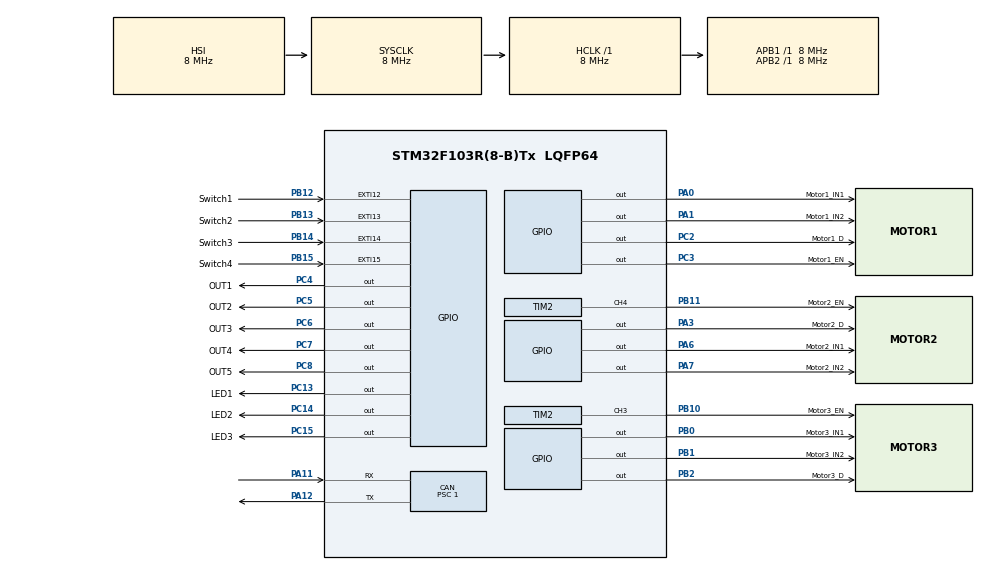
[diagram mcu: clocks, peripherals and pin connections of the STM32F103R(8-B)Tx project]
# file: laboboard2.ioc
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CAN.BS1=CAN_BS1_13TQ
CAN.BS2=CAN_BS2_2TQ
CAN.CalculateBaudRate=500000
CAN.CalculateTimeBit=2000
CAN.CalculateTimeQuantum=125.0
CAN.NART=ENABLE
CAN.Prescaler=1
Mcu.Family=STM32F1
Mcu.Name=STM32F103R(8-B)Tx
Mcu.Package=LQFP64
NVIC.CAN1_RX1_IRQn=true\:5\:0\:true\:false\:true\:true\:true\:true
NVIC.EXTI15_10_IRQn=true\:0\:0\:false\:false\:true\:true\:true\:true
NVIC.PriorityGroup=NVIC_PRIORITYGROUP_4
NVIC.TIM2_IRQn=true\:0\:0\:false\:false\:true\:true\:true\:true
NVIC.TIM3_IRQn=true\:2\:0\:true\:false\:true\:true\:true\:true
NVIC.USB_HP_CAN1_TX_IRQn=true\:5\:0\:true\:false\:true\:true\:true\:true
NVIC.USB_LP_CAN1_RX0_IRQn=true\:5\:0\:true\:false\:true\:true\:true\:true
PA0-WKUP.GPIO_Label=Motor1_IN1
PA0-WKUP.Signal=GPIO_Output
PA1.GPIO_Label=Motor1_IN2
PA1.Signal=GPIO_Output
PA11.Mode=CAN_Activate
PA11.Signal=CAN_RX
PA12.Mode=CAN_Activate
PA12.Signal=CAN_TX
PA13.Mode=Serial_Wire
PA13.Signal=SYS_JTMS-SWDIO
PA14.Mode=Serial_Wire
PA14.Signal=SYS_JTCK-SWCLK
PA3.GPIO_Label=Motor2_D
PA3.Signal=GPIO_Output
PA6.GPIO_Label=Motor2_IN1
PA6.Signal=GPIO_Output
PA7.GPIO_Label=Motor2_IN2
PA7.Signal=GPIO_Output
PB0.GPIO_Label=Motor3_IN1
PB0.Signal=GPIO_Output
PB1.GPIO_Label=Motor3_IN2
PB1.Signal=GPIO_Output
PB10.GPIO_Label=Motor3_EN
PB10.Signal=S_TIM2_CH3
PB11.GPIO_Label=Motor2_EN
PB11.Signal=S_TIM2_CH4
PB12.GPIO_Label=Switch1
PB12.GPIO_ModeDefaultEXTI=GPIO_MODE_IT_RISING_FALLING
PB12.GPIO_PuPd=GPIO_PULLDOWN
PB12.Signal=GPXTI12
PB13.GPIO_Label=Switch2
PB13.GPIO_ModeDefaultEXTI=GPIO_MODE_IT_RISING_FALLING
PB13.GPIO_PuPd=GPIO_PULLUP
PB13.Signal=GPXTI13
PB14.GPIO_Label=Switch3
PB14.GPIO_ModeDefaultEXTI=GPIO_MODE_IT_FALLING
PB14.GPIO_PuPd=GPIO_PULLUP
PB14.Signal=GPXTI14
PB15.GPIO_Label=Switch4
PB15.GPIO_ModeDefaultEXTI=GPIO_MODE_IT_FALLING
PB15.GPIO_PuPd=GPIO_PULLUP
PB15.Signal=GPXTI15
PB2.GPIO_Label=Motor3_D
PB2.Signal=GPIO_Output
PC13-TAMPER-RTC.GPIO_Label=LED1
PC13-TAMPER-RTC.Signal=GPIO_Output
PC14-OSC32_IN.GPIO_Label=LED2
PC14-OSC32_IN.Signal=GPIO_Output
PC15-OSC32_OUT.GPIO_Label=LED3
PC15-OSC32_OUT.Signal=GPIO_Output
PC2.GPIO_Label=Motor1_D
PC2.Signal=GPIO_Output
PC3.GPIO_Label=Motor1_EN
PC3.Signal=GPIO_Output
PC4.GPIO_Label=OUT1
PC4.Signal=GPIO_Output
PC5.GPIO_Label=OUT2
PC5.Signal=GPIO_Output
PC6.GPIO_Label=OUT3
PC6.Signal=GPIO_Output
PC7.GPIO_Label=OUT4
PC7.Signal=GPIO_Output
PC8.GPIO_Label=OUT5
PC8.Signal=GPIO_Output
ProjectManager.HeapSize=0x200
ProjectManager.StackSize=0x400
ProjectManager.TargetToolchain=STM32CubeIDE
RCC.AHBFreq_Value=8000000
RCC.APB1Freq_Value=8000000
RCC.APB1TimFreq_Value=8000000
RCC.APB2Freq_Value=8000000
RCC.APB2TimFreq_Value=8000000
RCC.HCLKFreq_Value=8000000
RCC.HSE_VALUE=16000000
RCC.SYSCLKFreq_VALUE=8000000
RCC.USBFreq_Value=8000000
SH.S_TIM2_CH3.0=TIM2_CH3,PWM Generation3 CH3
SH.S_TIM2_CH4.0=TIM2_CH4,PWM Generation4 CH4
TIM2.Channel-PWM\ Generation3\ CH3=TIM_CHANNEL_3
TIM2.Channel-PWM\ Generation4\ CH4=TIM_CHANNEL_4
TIM2.Period=99
TIM2.Prescaler=7
TIM3.Period=99
TIM3.Prescaler=3199
VP_TIM2_VS_ClockSourceINT.Mode=Internal
VP_TIM3_VS_ClockSourceINT.Mode=Internal
board=custom

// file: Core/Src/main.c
/* USER CODE BEGIN Header */
/**
  ******************************************************************************
  * @file           : main.c
  * @brief          : Main program body
  ******************************************************************************
  * @attention
  *
  * Copyright (c) 2025 STMicroelectronics.
  * All rights reserved.
  *
  * This software is licensed under terms that can be found in the LICENSE file
  * in the root directory of this software component.
  * If no LICENSE file comes with this software, it is provided AS-IS.
  *
  ******************************************************************************
  */
/* USER CODE END Header */
#include "main.h"
#include "can.h"
#include "tim.h"
#include "gpio.h"

/* USER CODE BEGIN PD */
int p =0;
/* USER CODE END PD */

void SystemClock_Config(void);

int main(void)
{

  /* MCU Configuration--------------------------------------------------------*/

  /* Reset of all peripherals, Initializes the Flash interface and the Systick. */
  HAL_Init();

  /* Configure the system clock */
  SystemClock_Config();

  /* Initialize all configured peripherals */
  MX_GPIO_Init();
  MX_CAN_Init();
  MX_TIM2_Init();
  MX_TIM3_Init();
  /* USER CODE BEGIN 2 */
  Motor_init();
  HAL_TIM_Base_Start_IT(&htim3);
  HAL_NVIC_DisableIRQ(TIM3_IRQn);
  if(HAL_GPIO_ReadPin(GPIOB, GPIO_PIN_12)==GPIO_PIN_SET)
  {
	  limit=-1;
  }
  if(HAL_GPIO_ReadPin(GPIOB, GPIO_PIN_13)==GPIO_PIN_RESET)
  {
	  limit=1;
  }
  /* USER CODE END 2 */

  /* Infinite loop */
  while (1)
  {

  }
}

void SystemClock_Config(void)
{
  RCC_OscInitTypeDef RCC_OscInitStruct = {0};
  RCC_ClkInitTypeDef RCC_ClkInitStruct = {0};

  /** Initializes the RCC Oscillators according to the specified parameters
  * in the RCC_OscInitTypeDef structure.
  */
  RCC_OscInitStruct.OscillatorType = RCC_OSCILLATORTYPE_HSI;
  RCC_OscInitStruct.HSIState = RCC_HSI_ON;
  RCC_OscInitStruct.HSICalibrationValue = RCC_HSICALIBRATION_DEFAULT;
  RCC_OscInitStruct.PLL.PLLState = RCC_PLL_NONE;
  if (HAL_RCC_OscConfig(&RCC_OscInitStruct) != HAL_OK)
  {
    Error_Handler();
  }

  /** Initializes the CPU, AHB and APB buses clocks
  */
  RCC_ClkInitStruct.ClockType = RCC_CLOCKTYPE_HCLK|RCC_CLOCKTYPE_SYSCLK
                              |RCC_CLOCKTYPE_PCLK1|RCC_CLOCKTYPE_PCLK2;
  RCC_ClkInitStruct.SYSCLKSource = RCC_SYSCLKSOURCE_HSI;
  RCC_ClkInitStruct.AHBCLKDivider = RCC_SYSCLK_DIV1;
  RCC_ClkInitStruct.APB1CLKDivider = RCC_HCLK_DIV1;
  RCC_ClkInitStruct.APB2CLKDivider = RCC_HCLK_DIV1;

  if (HAL_RCC_ClockConfig(&RCC_ClkInitStruct, FLASH_LATENCY_0) != HAL_OK)
  {
    Error_Handler();
  }
}

void Error_Handler(void)
{
  __disable_irq();
  while (1)
  {
  }
}
